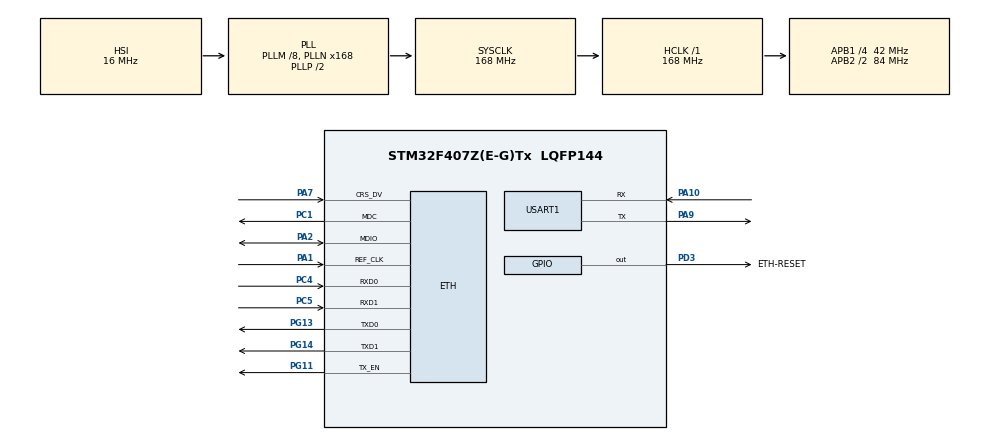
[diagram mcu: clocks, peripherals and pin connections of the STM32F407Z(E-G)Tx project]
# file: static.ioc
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Dma.Request0=USART1_RX
Dma.USART1_RX.0.Direction=DMA_PERIPH_TO_MEMORY
Dma.USART1_RX.0.FIFOMode=DMA_FIFOMODE_DISABLE
Dma.USART1_RX.0.Instance=DMA2_Stream2
Dma.USART1_RX.0.MemDataAlignment=DMA_MDATAALIGN_BYTE
Dma.USART1_RX.0.MemInc=DMA_MINC_ENABLE
Dma.USART1_RX.0.Mode=DMA_CIRCULAR
Dma.USART1_RX.0.PeriphDataAlignment=DMA_PDATAALIGN_BYTE
Dma.USART1_RX.0.PeriphInc=DMA_PINC_DISABLE
Dma.USART1_RX.0.Priority=DMA_PRIORITY_LOW
ETH.MediaInterface=HAL_ETH_RMII_MODE
LWIP.BSP.number=1
LWIP.GATEWAY_ADDRESS=192.168.000.001
LWIP.IP_ADDRESS=192.168.000.100
LWIP.LWIP_DHCP=1
LWIP.NETMASK_ADDRESS=255.255.255.000
LWIP.Version=v2.1.2_Cube
LWIP0.BSP.STBoard=false
LWIP0.BSP.api=BSP_COMPONENT_DRIVER
LWIP0.BSP.component=LAN8742
LWIP0.BSP.instance=LAN8742
LWIP0.BSP.name=Driver_PHY
LWIP0.BSP.semaphore=S_LAN8742
LWIP0.BSP.solution=LAN8742
Mcu.Family=STM32F4
Mcu.Name=STM32F407Z(E-G)Tx
Mcu.Package=LQFP144
NVIC.DMA2_Stream2_IRQn=true\:0\:0\:false\:false\:true\:false\:true\:true
NVIC.PriorityGroup=NVIC_PRIORITYGROUP_4
PA1.Mode=RMII
PA1.Signal=ETH_REF_CLK
PA10.Mode=Asynchronous
PA10.Signal=USART1_RX
PA13.Mode=Serial_Wire
PA13.Signal=SYS_JTMS-SWDIO
PA14.Mode=Serial_Wire
PA14.Signal=SYS_JTCK-SWCLK
PA2.Mode=RMII
PA2.Signal=ETH_MDIO
PA7.Mode=RMII
PA7.Signal=ETH_CRS_DV
PA9.Mode=Asynchronous
PA9.Signal=USART1_TX
PC1.Mode=RMII
PC1.Signal=ETH_MDC
PC4.Mode=RMII
PC4.Signal=ETH_RXD0
PC5.Mode=RMII
PC5.Signal=ETH_RXD1
PD3.GPIO_Label=ETH-RESET
PD3.PinState=GPIO_PIN_SET
PD3.Signal=GPIO_Output
PG11.Mode=RMII
PG11.Signal=ETH_TX_EN
PG13.Mode=RMII
PG13.Signal=ETH_TXD0
PG14.Mode=RMII
PG14.Signal=ETH_TXD1
PH0-OSC_IN.Mode=HSE-External-Oscillator
PH0-OSC_IN.Signal=RCC_OSC_IN
PH1-OSC_OUT.Mode=HSE-External-Oscillator
PH1-OSC_OUT.Signal=RCC_OSC_OUT
ProjectManager.HeapSize=0x200
ProjectManager.StackSize=0x400
ProjectManager.TargetToolchain=MDK-ARM V5.32
RCC.48MHZClocksFreq_Value=84000000
RCC.AHBFreq_Value=168000000
RCC.APB1CLKDivider=RCC_HCLK_DIV4
RCC.APB1Freq_Value=42000000
RCC.APB1TimFreq_Value=84000000
RCC.APB2CLKDivider=RCC_HCLK_DIV2
RCC.APB2Freq_Value=84000000
RCC.APB2TimFreq_Value=168000000
RCC.CortexFreq_Value=168000000
RCC.HCLKFreq_Value=168000000
RCC.HSE_VALUE=25000000
RCC.HSI_VALUE=16000000
RCC.LSE_VALUE=32768
RCC.PLLM=8
RCC.PLLN=168
RCC.SYSCLKFreq_VALUE=168000000
RCC.SYSCLKSource=RCC_SYSCLKSOURCE_PLLCLK
RCC.VCOOutputFreq_Value=336000000
USART1.VirtualMode=VM_ASYNC
VP_LWIP_VS_Enabled.Mode=Enabled
board=custom

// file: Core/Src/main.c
/* USER CODE BEGIN Header */
/**
  ******************************************************************************
  * @file           : main.c
  * @brief          : Main program body
  ******************************************************************************
  * @attention
  *
  * Copyright (c) 2026 STMicroelectronics.
  * All rights reserved.
  *
  * This software is licensed under terms that can be found in the LICENSE file
  * in the root directory of this software component.
  * If no LICENSE file comes with this software, it is provided AS-IS.
  *
  ******************************************************************************
  */
/* USER CODE END Header */
#include "main.h"
#include "dma.h"
#include "lwip.h"
#include "usart.h"
#include "gpio.h"

/* USER CODE BEGIN Includes */
#include <stdio.h>
//#include "tcpserver.h"
/* USER CODE END Includes */

void SystemClock_Config(void);
/* USER CODE BEGIN PFP */
extern struct netif gnetif;
struct dhcp *dhcp;
/* USER CODE END PFP */

int main(void)
{

  /* MCU Configuration--------------------------------------------------------*/

  /* Reset of all peripherals, Initializes the Flash interface and the Systick. */
  HAL_Init();

  /* Configure the system clock */
  SystemClock_Config();

  /* Initialize all configured peripherals */
  MX_GPIO_Init();
  MX_DMA_Init();
  MX_USART1_UART_Init();
  MX_LWIP_Init();
  /* USER CODE BEGIN 2 */
	__HAL_UART_ENABLE_IT(&huart1, UART_IT_IDLE); //ʹ�ܴ�UART1 IDLE(����)�ж�
	HAL_UART_Receive_DMA(&huart1, RX1_Buf, DMA_BUF_SIZE); //����DMA���䣬��uart1�����ݰ��˵�RX1_Buf��
		printf("Uart1 init is ok\n");
//	tcp_server_start(8000);
	printf("Static IP address: %s\n", ip4addr_ntoa(&gnetif.ip_addr));
	printf("Subnet mask      : %s\n", ip4addr_ntoa(&gnetif.netmask));
	printf("Default gateway  : %s\n", ip4addr_ntoa(&gnetif.gw));
  /* USER CODE END 2 */

  /* Infinite loop */
  while (1)
  {
		MX_LWIP_Process();
				dhcp = netif_dhcp_data(&gnetif);
		printf("DHCP IP address: %s\n", ip4addr_ntoa(&dhcp->offered_ip_addr));
		printf("DHCP Subnet mask: %s\n", ip4addr_ntoa(&dhcp->offered_sn_mask));
		printf("DHCP Default gateway: %s\n", ip4addr_ntoa(&dhcp->offered_gw_addr));
		HAL_Delay(1000);
  }
}

void SystemClock_Config(void)
{
  RCC_OscInitTypeDef RCC_OscInitStruct = {0};
  RCC_ClkInitTypeDef RCC_ClkInitStruct = {0};

  /** Configure the main internal regulator output voltage
  */
  __HAL_RCC_PWR_CLK_ENABLE();
  __HAL_PWR_VOLTAGESCALING_CONFIG(PWR_REGULATOR_VOLTAGE_SCALE1);

  /** Initializes the RCC Oscillators according to the specified parameters
  * in the RCC_OscInitTypeDef structure.
  */
  RCC_OscInitStruct.OscillatorType = RCC_OSCILLATORTYPE_HSI;
  RCC_OscInitStruct.HSIState = RCC_HSI_ON;
  RCC_OscInitStruct.HSICalibrationValue = RCC_HSICALIBRATION_DEFAULT;
  RCC_OscInitStruct.PLL.PLLState = RCC_PLL_ON;
  RCC_OscInitStruct.PLL.PLLSource = RCC_PLLSOURCE_HSI;
  RCC_OscInitStruct.PLL.PLLM = 8;
  RCC_OscInitStruct.PLL.PLLN = 168;
  RCC_OscInitStruct.PLL.PLLP = RCC_PLLP_DIV2;
  RCC_OscInitStruct.PLL.PLLQ = 4;
  if (HAL_RCC_OscConfig(&RCC_OscInitStruct) != HAL_OK)
  {
    Error_Handler();
  }

  /** Initializes the CPU, AHB and APB buses clocks
  */
  RCC_ClkInitStruct.ClockType = RCC_CLOCKTYPE_HCLK|RCC_CLOCKTYPE_SYSCLK
                              |RCC_CLOCKTYPE_PCLK1|RCC_CLOCKTYPE_PCLK2;
  RCC_ClkInitStruct.SYSCLKSource = RCC_SYSCLKSOURCE_PLLCLK;
  RCC_ClkInitStruct.AHBCLKDivider = RCC_SYSCLK_DIV1;
  RCC_ClkInitStruct.APB1CLKDivider = RCC_HCLK_DIV4;
  RCC_ClkInitStruct.APB2CLKDivider = RCC_HCLK_DIV2;

  if (HAL_RCC_ClockConfig(&RCC_ClkInitStruct, FLASH_LATENCY_5) != HAL_OK)
  {
    Error_Handler();
  }
}

void Error_Handler(void)
{
  __disable_irq();
  while (1)
  {
  }
}
